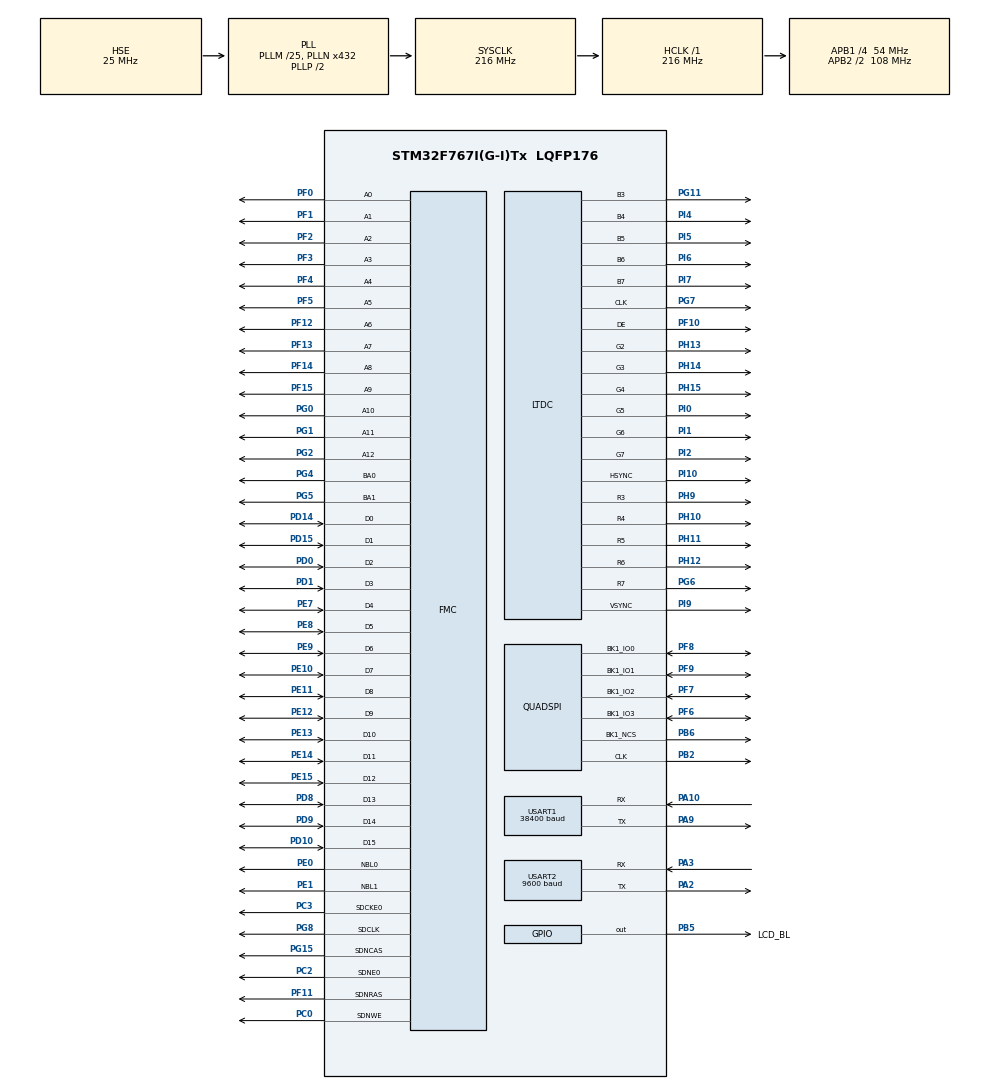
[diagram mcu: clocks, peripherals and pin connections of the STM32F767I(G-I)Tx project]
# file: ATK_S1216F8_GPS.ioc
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CORTEX_M7.AccessPermission_Spec=MPU_REGION_FULL_ACCESS
CORTEX_M7.BaseAddress_Spec=0xC0000000
CORTEX_M7.CPU_DCache=Enabled
CORTEX_M7.CPU_ICache=Enabled
CORTEX_M7.DisableExec_Spec=MPU_INSTRUCTION_ACCESS_ENABLE
CORTEX_M7.Enable_S-Cortex_Memory_Protection_Unit_Region1_Settings_S=__NULL
CORTEX_M7.FlashInterface=TCM_Enabled
CORTEX_M7.IsBufferable_Spec=MPU_ACCESS_BUFFERABLE
CORTEX_M7.IsCacheable_Spec=MPU_ACCESS_CACHEABLE
CORTEX_M7.MPU_Control=MPU_HFNMI_PRIVDEF
CORTEX_M7.Size_Spec=MPU_REGION_SIZE_32MB
CORTEX_M7.SubRegionDisable_Spec=0x0
CORTEX_M7.default_mode_Activation=1
DMA2D.ColorMode=DMA2D_OUTPUT_RGB565
FMC.CASLatency1=FMC_SDRAM_CAS_LATENCY_3
FMC.ColumnBitsNumber1=FMC_SDRAM_COLUMN_BITS_NUM_9
FMC.ExitSelfRefreshDelay1=8
FMC.LoadToActiveDelay1=2
FMC.RCDDelay1=2
FMC.RPDelay1=2
FMC.RPDelay2=2
FMC.ReadBurst1=FMC_SDRAM_RBURST_ENABLE
FMC.ReadBurst2=FMC_SDRAM_RBURST_ENABLE
FMC.ReadPipeDelay1=FMC_SDRAM_RPIPE_DELAY_1
FMC.ReadPipeDelay2=FMC_SDRAM_RPIPE_DELAY_1
FMC.RowCycleDelay1=6
FMC.RowCycleDelay2=6
FMC.SDClockPeriod1=FMC_SDRAM_CLOCK_PERIOD_2
FMC.SDClockPeriod2=FMC_SDRAM_CLOCK_PERIOD_2
FMC.SelfRefreshTime1=6
FMC.WriteRecoveryTime1=4
FREERTOS.Tasks01=TouchGFXTask,0,6144,StartTouchGFXask,Default,NULL,Dynamic,NULL,NULL;Task02,0,1024,StartTask02,Default,NULL,Dynamic,NULL,NULL
FREERTOS.configENABLE_FPU=1
FREERTOS.configTOTAL_HEAP_SIZE=61440
FREERTOS.configUSE_APPLICATION_TASK_TAG=1
FREERTOS.configUSE_NEWLIB_REENTRANT=1
LTDC.ActiveH=LCD_HEIGHT
LTDC.ActiveW=LCD_WIDTH
LTDC.Alpha_L0=0xFF
LTDC.FBStartAdress_L0=LAYER0_ADDR
LTDC.HBP=140
LTDC.HFP=160
LTDC.HSync=20
LTDC.ImageHeight_L0=LCD_HEIGHT
LTDC.ImageWidth_L0=LCD_WIDTH
LTDC.Layers=0
LTDC.PixelFormat_L0=LTDC_PIXEL_FORMAT_RGB565
LTDC.VBP=20
LTDC.VFP=12
LTDC.VSync=3
LTDC.WindowX1_L0=LCD_WIDTH
LTDC.WindowY1_L0=LCD_HEIGHT
Mcu.Family=STM32F7
Mcu.Name=STM32F767I(G-I)Tx
Mcu.Package=LQFP176
Mcu.UserConstants=LAYER0_ADDR,0xC0000000;LCD_HEIGHT,600;LCD_WIDTH,1024
NVIC.DMA2D_IRQn=true\:5\:0\:false\:false\:true\:true\:true\:true\:true
NVIC.FMC_IRQn=true\:5\:0\:false\:false\:true\:true\:true\:true\:true
NVIC.FPU_IRQn=true\:5\:0\:false\:false\:true\:true\:true\:false\:true
NVIC.LTDC_ER_IRQn=true\:5\:0\:false\:false\:true\:true\:true\:true\:true
NVIC.LTDC_IRQn=true\:5\:0\:false\:false\:true\:true\:true\:true\:true
NVIC.PriorityGroup=NVIC_PRIORITYGROUP_4
NVIC.QUADSPI_IRQn=true\:5\:0\:false\:false\:true\:true\:true\:true\:true
NVIC.TIM7_IRQn=true\:0\:0\:true\:false\:true\:false\:false\:true\:true
NVIC.TimeBase=TIM7_IRQn
NVIC.TimeBaseIP=TIM7
NVIC.USART1_IRQn=true\:5\:0\:false\:false\:true\:true\:true\:true\:true
NVIC.USART2_IRQn=true\:5\:0\:false\:false\:true\:true\:true\:true\:true
PA10.Mode=Asynchronous
PA10.Signal=USART1_RX
PA13.Mode=Trace_Asynchronous_SW
PA13.Signal=SYS_JTMS-SWDIO
PA14.Mode=Trace_Asynchronous_SW
PA14.Signal=SYS_JTCK-SWCLK
PA2.Mode=Asynchronous
PA2.Signal=USART2_TX
PA3.Mode=Asynchronous
PA3.Signal=USART2_RX
PA9.Mode=Asynchronous
PA9.Signal=USART1_TX
PB2.Mode=Single Bank 1
PB2.Signal=QUADSPI_CLK
PB3.Mode=Trace_Asynchronous_SW
PB3.Signal=SYS_JTDO-SWO
PB5.GPIO_Label=LCD_BL
PB5.GPIO_PuPd=GPIO_PULLUP
PB5.GPIO_Speed=GPIO_SPEED_FREQ_VERY_HIGH
PB5.PinState=GPIO_PIN_SET
PB5.Signal=GPIO_Output
PB6.Mode=Single Bank 1
PB6.Signal=QUADSPI_BK1_NCS
PC0.Signal=FMC_SDNWE
PC2.Mode=SdramChipSelect1_1
PC2.Signal=FMC_SDNE0
PC3.Mode=SdramChipSelect1_1
PC3.Signal=FMC_SDCKE0
PD0.Signal=FMC_D2_DA2
PD1.Signal=FMC_D3_DA3
PD10.Signal=FMC_D15_DA15
PD14.Signal=FMC_D0_DA0
PD15.Signal=FMC_D1_DA1
PD8.Signal=FMC_D13_DA13
PD9.Signal=FMC_D14_DA14
PE0.Signal=FMC_NBL0
PE1.Signal=FMC_NBL1
PE10.Signal=FMC_D7_DA7
PE11.Signal=FMC_D8_DA8
PE12.Signal=FMC_D9_DA9
PE13.Signal=FMC_D10_DA10
PE14.Signal=FMC_D11_DA11
PE15.Signal=FMC_D12_DA12
PE7.Signal=FMC_D4_DA4
PE8.Signal=FMC_D5_DA5
PE9.Signal=FMC_D6_DA6
PF0.Signal=FMC_A0
PF1.Signal=FMC_A1
PF10.GPIO_Mode=GPIO_MODE_AF_PP
PF10.GPIO_PuPd=GPIO_PULLUP
PF10.GPIO_Speed=GPIO_SPEED_FREQ_VERY_HIGH
PF10.Mode=RGB565
PF10.Signal=LTDC_DE
PF11.Signal=FMC_SDNRAS
PF12.Signal=FMC_A6
PF13.Signal=FMC_A7
PF14.Signal=FMC_A8
PF15.Signal=FMC_A9
PF2.Signal=FMC_A2
PF3.Signal=FMC_A3
PF4.Signal=FMC_A4
PF5.Signal=FMC_A5
PF6.Mode=Single Bank 1
PF6.Signal=QUADSPI_BK1_IO3
PF7.Mode=Single Bank 1
PF7.Signal=QUADSPI_BK1_IO2
PF8.Mode=Single Bank 1
PF8.Signal=QUADSPI_BK1_IO0
PF9.Mode=Single Bank 1
PF9.Signal=QUADSPI_BK1_IO1
PG0.Signal=FMC_A10
PG1.Signal=FMC_A11
PG11.GPIO_Mode=GPIO_MODE_AF_PP
PG11.GPIO_PuPd=GPIO_PULLUP
PG11.GPIO_Speed=GPIO_SPEED_FREQ_VERY_HIGH
PG11.Mode=RGB565
PG11.Signal=LTDC_B3
PG15.Signal=FMC_SDNCAS
PG2.Signal=FMC_A12
PG4.Signal=FMC_A14_BA0
PG5.Signal=FMC_A15_BA1
PG6.GPIO_Mode=GPIO_MODE_AF_PP
PG6.GPIO_PuPd=GPIO_PULLUP
PG6.GPIO_Speed=GPIO_SPEED_FREQ_VERY_HIGH
PG6.Mode=RGB565
PG6.Signal=LTDC_R7
PG7.GPIO_Mode=GPIO_MODE_AF_PP
PG7.GPIO_PuPd=GPIO_PULLUP
PG7.GPIO_Speed=GPIO_SPEED_FREQ_VERY_HIGH
PG7.Mode=RGB565
PG7.Signal=LTDC_CLK
PG8.Signal=FMC_SDCLK
PH0/OSC_IN.Mode=HSE-External-Oscillator
PH0/OSC_IN.Signal=RCC_OSC_IN
PH1/OSC_OUT.Mode=HSE-External-Oscillator
PH1/OSC_OUT.Signal=RCC_OSC_OUT
PH10.GPIO_Mode=GPIO_MODE_AF_PP
PH10.GPIO_PuPd=GPIO_PULLUP
PH10.GPIO_Speed=GPIO_SPEED_FREQ_VERY_HIGH
PH10.Mode=RGB565
PH10.Signal=LTDC_R4
PH11.GPIO_Mode=GPIO_MODE_AF_PP
PH11.GPIO_PuPd=GPIO_PULLUP
PH11.GPIO_Speed=GPIO_SPEED_FREQ_VERY_HIGH
PH11.Mode=RGB565
PH11.Signal=LTDC_R5
PH12.GPIO_Mode=GPIO_MODE_AF_PP
PH12.GPIO_PuPd=GPIO_PULLUP
PH12.GPIO_Speed=GPIO_SPEED_FREQ_VERY_HIGH
PH12.Mode=RGB565
PH12.Signal=LTDC_R6
PH13.GPIO_Mode=GPIO_MODE_AF_PP
PH13.GPIO_PuPd=GPIO_PULLUP
PH13.GPIO_Speed=GPIO_SPEED_FREQ_VERY_HIGH
PH13.Mode=RGB565
PH13.Signal=LTDC_G2
PH14.GPIO_Mode=GPIO_MODE_AF_PP
PH14.GPIO_PuPd=GPIO_PULLUP
PH14.GPIO_Speed=GPIO_SPEED_FREQ_VERY_HIGH
PH14.Mode=RGB565
PH14.Signal=LTDC_G3
PH15.GPIO_Mode=GPIO_MODE_AF_PP
PH15.GPIO_PuPd=GPIO_PULLUP
PH15.GPIO_Speed=GPIO_SPEED_FREQ_VERY_HIGH
PH15.Mode=RGB565
PH15.Signal=LTDC_G4
PH9.GPIO_Mode=GPIO_MODE_AF_PP
PH9.GPIO_PuPd=GPIO_PULLUP
PH9.GPIO_Speed=GPIO_SPEED_FREQ_VERY_HIGH
PH9.Mode=RGB565
PH9.Signal=LTDC_R3
PI0.GPIO_Mode=GPIO_MODE_AF_PP
PI0.GPIO_PuPd=GPIO_PULLUP
PI0.GPIO_Speed=GPIO_SPEED_FREQ_VERY_HIGH
PI0.Mode=RGB565
PI0.Signal=LTDC_G5
PI1.GPIO_Mode=GPIO_MODE_AF_PP
PI1.GPIO_PuPd=GPIO_PULLUP
PI1.GPIO_Speed=GPIO_SPEED_FREQ_VERY_HIGH
PI1.Mode=RGB565
PI1.Signal=LTDC_G6
PI10.GPIO_Mode=GPIO_MODE_AF_PP
PI10.GPIO_PuPd=GPIO_PULLUP
PI10.GPIO_Speed=GPIO_SPEED_FREQ_VERY_HIGH
PI10.Mode=RGB565
PI10.Signal=LTDC_HSYNC
PI2.GPIO_Mode=GPIO_MODE_AF_PP
PI2.GPIO_PuPd=GPIO_PULLUP
PI2.GPIO_Speed=GPIO_SPEED_FREQ_VERY_HIGH
PI2.Mode=RGB565
PI2.Signal=LTDC_G7
PI4.GPIO_Mode=GPIO_MODE_AF_PP
PI4.GPIO_PuPd=GPIO_PULLUP
PI4.GPIO_Speed=GPIO_SPEED_FREQ_VERY_HIGH
PI4.Mode=RGB565
PI4.Signal=LTDC_B4
PI5.GPIO_Mode=GPIO_MODE_AF_PP
PI5.GPIO_PuPd=GPIO_PULLUP
PI5.GPIO_Speed=GPIO_SPEED_FREQ_VERY_HIGH
PI5.Mode=RGB565
PI5.Signal=LTDC_B5
PI6.GPIO_Mode=GPIO_MODE_AF_PP
PI6.GPIO_PuPd=GPIO_PULLUP
PI6.GPIO_Speed=GPIO_SPEED_FREQ_VERY_HIGH
PI6.Mode=RGB565
PI6.Signal=LTDC_B6
PI7.GPIO_Mode=GPIO_MODE_AF_PP
PI7.GPIO_PuPd=GPIO_PULLUP
PI7.GPIO_Speed=GPIO_SPEED_FREQ_VERY_HIGH
PI7.Mode=RGB565
PI7.Signal=LTDC_B7
PI9.GPIO_Mode=GPIO_MODE_AF_PP
PI9.GPIO_PuPd=GPIO_PULLUP
PI9.GPIO_Speed=GPIO_SPEED_FREQ_VERY_HIGH
PI9.Mode=RGB565
PI9.Signal=LTDC_VSYNC
ProjectManager.HeapSize=0x200
ProjectManager.StackSize=0x400
ProjectManager.TargetToolchain=STM32CubeIDE
QUADSPI.ChipSelectHighTime=QSPI_CS_HIGH_TIME_4_CYCLE
QUADSPI.ClockMode=QSPI_CLOCK_MODE_3
QUADSPI.ClockPrescaler=2
QUADSPI.FifoThreshold=4
QUADSPI.SampleShifting=QSPI_SAMPLE_SHIFTING_HALFCYCLE
RCC.AHBFreq_Value=216000000
RCC.APB1CLKDivider=RCC_HCLK_DIV4
RCC.APB1Freq_Value=54000000
RCC.APB1TimFreq_Value=108000000
RCC.APB2CLKDivider=RCC_HCLK_DIV2
RCC.APB2Freq_Value=108000000
RCC.APB2TimFreq_Value=216000000
RCC.CortexFreq_Value=216000000
RCC.HCLKFreq_Value=216000000
RCC.HSE_VALUE=25000000
RCC.HSI_VALUE=16000000
RCC.LSE_VALUE=32768
RCC.PLLM=25
RCC.PLLN=432
RCC.PLLSAIN=408
RCC.PLLSAIR=4
RCC.PLLSourceVirtual=RCC_PLLSOURCE_HSE
RCC.SYSCLKFreq_VALUE=216000000
RCC.SYSCLKSource=RCC_SYSCLKSOURCE_PLLCLK
RCC.USBFreq_Value=216000000
RCC.VCOOutputFreq_Value=432000000
SH.FMC_A0.0=FMC_A0,13b-sda1
SH.FMC_A1.0=FMC_A1,13b-sda1
SH.FMC_A10.0=FMC_A10,13b-sda1
SH.FMC_A11.0=FMC_A11,13b-sda1
SH.FMC_A12.0=FMC_A12,13b-sda1
SH.FMC_A14_BA0.0=FMC_BA0,FourSdramBanks1
SH.FMC_A15_BA1.0=FMC_BA1,FourSdramBanks1
SH.FMC_A2.0=FMC_A2,13b-sda1
SH.FMC_A3.0=FMC_A3,13b-sda1
SH.FMC_A4.0=FMC_A4,13b-sda1
SH.FMC_A5.0=FMC_A5,13b-sda1
SH.FMC_A6.0=FMC_A6,13b-sda1
SH.FMC_A7.0=FMC_A7,13b-sda1
SH.FMC_A8.0=FMC_A8,13b-sda1
SH.FMC_A9.0=FMC_A9,13b-sda1
SH.FMC_D0_DA0.0=FMC_D0,sd-16b-d1
SH.FMC_D10_DA10.0=FMC_D10,sd-16b-d1
SH.FMC_D11_DA11.0=FMC_D11,sd-16b-d1
SH.FMC_D12_DA12.0=FMC_D12,sd-16b-d1
SH.FMC_D13_DA13.0=FMC_D13,sd-16b-d1
SH.FMC_D14_DA14.0=FMC_D14,sd-16b-d1
SH.FMC_D15_DA15.0=FMC_D15,sd-16b-d1
SH.FMC_D1_DA1.0=FMC_D1,sd-16b-d1
SH.FMC_D2_DA2.0=FMC_D2,sd-16b-d1
SH.FMC_D3_DA3.0=FMC_D3,sd-16b-d1
SH.FMC_D4_DA4.0=FMC_D4,sd-16b-d1
SH.FMC_D5_DA5.0=FMC_D5,sd-16b-d1
SH.FMC_D6_DA6.0=FMC_D6,sd-16b-d1
SH.FMC_D7_DA7.0=FMC_D7,sd-16b-d1
SH.FMC_D8_DA8.0=FMC_D8,sd-16b-d1
SH.FMC_D9_DA9.0=FMC_D9,sd-16b-d1
SH.FMC_NBL0.0=FMC_NBL0,Sd2ByteEnable1
SH.FMC_NBL1.0=FMC_NBL1,Sd2ByteEnable1
SH.FMC_SDCLK.0=FMC_SDCLK,13b-sda1
SH.FMC_SDNCAS.0=FMC_SDNCAS,13b-sda1
SH.FMC_SDNRAS.0=FMC_SDNRAS,13b-sda1
SH.FMC_SDNWE.0=FMC_SDNWE,13b-sda1
STMicroelectronics.X-CUBE-TOUCHGFX.4.18.1.ApplicationCcGraphicsJjApplication=TouchGFXOoGenerator
STMicroelectronics.X-CUBE-TOUCHGFX.4.18.1.tgfx_address1=0xC0000000
STMicroelectronics.X-CUBE-TOUCHGFX.4.18.1.tgfx_address2=0xC012C000
STMicroelectronics.X-CUBE-TOUCHGFX.4.18.1.tgfx_buffering_strategy=Double
STMicroelectronics.X-CUBE-TOUCHGFX.4.18.1.tgfx_display_interface=disp_ltdc
STMicroelectronics.X-CUBE-TOUCHGFX.4.18.1.tgfx_hardware_accelerator=dma_2d
STMicroelectronics.X-CUBE-TOUCHGFX.4.18.1.tgfx_location=By Address
STMicroelectronics.X-CUBE-TOUCHGFX.4.18.1.tgfx_vsync=vsync_ltdc
STMicroelectronics.X-CUBE-TOUCHGFX.4.18.1_IsPackSelfContextualization=true
USART1.BaudRate=38400
USART1.VirtualMode-Asynchronous=VM_ASYNC
USART2.BaudRate=9600
USART2.VirtualMode-Asynchronous=VM_ASYNC
VP_CRC_VS_CRC.Mode=CRC_Activate
VP_DMA2D_VS_DMA2D.Mode=DMA2D_Activate
VP_FREERTOS_VS_CMSIS_V1.Mode=CMSIS_V1
VP_STMicroelectronics.X-CUBE-TOUCHGFX_VS_GraphicsJjApplication_4.18.1.Mode=GraphicsJjApplication
VP_SYS_VS_tim7.Mode=TIM7
board=custom

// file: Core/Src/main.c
/* USER CODE BEGIN Header */
/**
 ******************************************************************************
 * @file           : main.c
 * @brief          : Main program body
 ******************************************************************************
 * @attention
 *
 * Copyright (c) 2022 STMicroelectronics.
 * All rights reserved.
 *
 * This software is licensed under terms that can be found in the LICENSE file
 * in the root directory of this software component.
 * If no LICENSE file comes with this software, it is provided AS-IS.
 *
 ******************************************************************************
 */
/* USER CODE END Header */
#include "main.h"
#include "cmsis_os.h"
#include "crc.h"
#include "dma2d.h"
#include "ltdc.h"
#include "quadspi.h"
#include "usart.h"
#include "gpio.h"
#include "fmc.h"
#include "app_touchgfx.h"

/* USER CODE BEGIN Includes */
#include "sensors.h"
#include <stdio.h>
/* USER CODE END Includes */

/* USER CODE BEGIN PD */
#define REFRESH_COUNT 1755

#define SDRAM_TIMEOUT ((uint32_t)0xFFFF)
#define SDRAM_MODEREG_BURST_LENGTH_1 ((uint16_t)0x0000)
#define SDRAM_MODEREG_BURST_LENGTH_2 ((uint16_t)0x0001)
#define SDRAM_MODEREG_BURST_LENGTH_4 ((uint16_t)0x0002)
#define SDRAM_MODEREG_BURST_LENGTH_8 ((uint16_t)0x0004)
#define SDRAM_MODEREG_BURST_TYPE_SEQUENTIAL ((uint16_t)0x0000)
#define SDRAM_MODEREG_BURST_TYPE_INTERLEAVED ((uint16_t)0x0008)
#define SDRAM_MODEREG_CAS_LATENCY_2 ((uint16_t)0x0020)
#define SDRAM_MODEREG_CAS_LATENCY_3 ((uint16_t)0x0030)
#define SDRAM_MODEREG_OPERATING_MODE_STANDARD ((uint16_t)0x0000)
#define SDRAM_MODEREG_WRITEBURST_MODE_PROGRAMMED ((uint16_t)0x0000)
#define SDRAM_MODEREG_WRITEBURST_MODE_SINGLE ((uint16_t)0x0200)
/* USER CODE END PD */

/* USER CODE BEGIN PV */
static FMC_SDRAM_CommandTypeDef Command;
/* USER CODE END PV */

void SystemClock_Config(void);
static void MPU_Config(void);
void MX_FREERTOS_Init(void);

int main(void)
{

  /* MPU Configuration--------------------------------------------------------*/
  MPU_Config();

  /* Enable I-Cache---------------------------------------------------------*/
  SCB_EnableICache();

  /* Enable D-Cache---------------------------------------------------------*/
  SCB_EnableDCache();

  /* MCU Configuration--------------------------------------------------------*/

  /* Reset of all peripherals, Initializes the Flash interface and the Systick. */
  HAL_Init();

  /* Configure the system clock */
  SystemClock_Config();

  /* Initialize all configured peripherals */
  MX_GPIO_Init();
  MX_USART1_UART_Init();
  MX_USART2_UART_Init();
  MX_DMA2D_Init();
  MX_FMC_Init();
  MX_QUADSPI_Init();
  MX_CRC_Init();
  MX_LTDC_Init();
  MX_TouchGFX_Init();
  /* USER CODE BEGIN 2 */
  MX_SDRAM_InitEx();
  HAL_UART_Receive_IT(&huart1, (uint8_t *)UART1_temp, REC_LENGTH);
  printf("USART2 IS OK!!!\r\n");
  /* USER CODE END 2 */

  /* Call init function for freertos objects (in freertos.c) */
  MX_FREERTOS_Init();

  /* Start scheduler */
  osKernelStart();

  /* We should never get here as control is now taken by the scheduler */
  /* Infinite loop */
  while (1) {

  }
}

void SystemClock_Config(void)
{
  RCC_OscInitTypeDef RCC_OscInitStruct = {0};
  RCC_ClkInitTypeDef RCC_ClkInitStruct = {0};

  /** Configure the main internal regulator output voltage
  */
  __HAL_RCC_PWR_CLK_ENABLE();
  __HAL_PWR_VOLTAGESCALING_CONFIG(PWR_REGULATOR_VOLTAGE_SCALE1);

  /** Initializes the RCC Oscillators according to the specified parameters
  * in the RCC_OscInitTypeDef structure.
  */
  RCC_OscInitStruct.OscillatorType = RCC_OSCILLATORTYPE_HSE;
  RCC_OscInitStruct.HSEState = RCC_HSE_ON;
  RCC_OscInitStruct.PLL.PLLState = RCC_PLL_ON;
  RCC_OscInitStruct.PLL.PLLSource = RCC_PLLSOURCE_HSE;
  RCC_OscInitStruct.PLL.PLLM = 25;
  RCC_OscInitStruct.PLL.PLLN = 432;
  RCC_OscInitStruct.PLL.PLLP = RCC_PLLP_DIV2;
  RCC_OscInitStruct.PLL.PLLQ = 2;
  RCC_OscInitStruct.PLL.PLLR = 2;
  if (HAL_RCC_OscConfig(&RCC_OscInitStruct) != HAL_OK)
  {
    Error_Handler();
  }

  /** Activate the Over-Drive mode
  */
  if (HAL_PWREx_EnableOverDrive() != HAL_OK)
  {
    Error_Handler();
  }

  /** Initializes the CPU, AHB and APB buses clocks
  */
  RCC_ClkInitStruct.ClockType = RCC_CLOCKTYPE_HCLK|RCC_CLOCKTYPE_SYSCLK
                              |RCC_CLOCKTYPE_PCLK1|RCC_CLOCKTYPE_PCLK2;
  RCC_ClkInitStruct.SYSCLKSource = RCC_SYSCLKSOURCE_PLLCLK;
  RCC_ClkInitStruct.AHBCLKDivider = RCC_SYSCLK_DIV1;
  RCC_ClkInitStruct.APB1CLKDivider = RCC_HCLK_DIV4;
  RCC_ClkInitStruct.APB2CLKDivider = RCC_HCLK_DIV2;

  if (HAL_RCC_ClockConfig(&RCC_ClkInitStruct, FLASH_LATENCY_7) != HAL_OK)
  {
    Error_Handler();
  }
}

/* USER CODE BEGIN 4 */
/**
 * @brief  Programs the SDRAM device.
 * @retval None
 */
void MX_SDRAM_InitEx(void) {
  __IO uint32_t tmpmrd = 0;

  /* Step 1: Configure a clock configuration enable command */
  Command.CommandMode = FMC_SDRAM_CMD_CLK_ENABLE;
  Command.CommandTarget = FMC_SDRAM_CMD_TARGET_BANK1;
  Command.AutoRefreshNumber = 1;
  Command.ModeRegisterDefinition = 0;

  /* Send the command */
  HAL_SDRAM_SendCommand(&hsdram1, &Command, SDRAM_TIMEOUT);

  /* Step 2: Insert 100 us minimum delay */
  /* Inserted delay is equal to 1 ms due to systick time base unit (ms) */
  HAL_Delay(1);

  /* Step 3: Configure a PALL (precharge all) command */
  Command.CommandMode = FMC_SDRAM_CMD_PALL;
  Command.CommandTarget = FMC_SDRAM_CMD_TARGET_BANK1;
  Command.AutoRefreshNumber = 1;
  Command.ModeRegisterDefinition = 0;

  /* Send the command */
  HAL_SDRAM_SendCommand(&hsdram1, &Command, SDRAM_TIMEOUT);

  /* Step 4: Configure an Auto Refresh command */
  Command.CommandMode = FMC_SDRAM_CMD_AUTOREFRESH_MODE;
  Command.CommandTarget = FMC_SDRAM_CMD_TARGET_BANK1;
  Command.AutoRefreshNumber = 8;
  Command.ModeRegisterDefinition = 0;

  /* Send the command */
  HAL_SDRAM_SendCommand(&hsdram1, &Command, SDRAM_TIMEOUT);

  /* Step 5: Program the external memory mode register */
  tmpmrd = (uint32_t)SDRAM_MODEREG_BURST_LENGTH_1 |
           SDRAM_MODEREG_BURST_TYPE_SEQUENTIAL | SDRAM_MODEREG_CAS_LATENCY_3 |
           SDRAM_MODEREG_OPERATING_MODE_STANDARD |
           SDRAM_MODEREG_WRITEBURST_MODE_SINGLE;

  Command.CommandMode = FMC_SDRAM_CMD_LOAD_MODE;
  Command.CommandTarget = FMC_SDRAM_CMD_TARGET_BANK1;
  Command.AutoRefreshNumber = 1;
  Command.ModeRegisterDefinition = tmpmrd;

  /* Send the command */
  HAL_SDRAM_SendCommand(&hsdram1, &Command, SDRAM_TIMEOUT);

  /* Step 6: Set the refresh rate counter */
  /* Set the device refresh rate */
  HAL_SDRAM_ProgramRefreshRate(&hsdram1, REFRESH_COUNT);
}
/* USER CODE END 4 */

/* MPU Configuration */

void MPU_Config(void)
{
  MPU_Region_InitTypeDef MPU_InitStruct = {0};

  /* Disables the MPU */
  HAL_MPU_Disable();

  /** Initializes and configures the Region and the memory to be protected
  */
  MPU_InitStruct.Enable = MPU_REGION_ENABLE;
  MPU_InitStruct.Number = MPU_REGION_NUMBER0;
  MPU_InitStruct.BaseAddress = 0xC0000000;
  MPU_InitStruct.Size = MPU_REGION_SIZE_32MB;
  MPU_InitStruct.SubRegionDisable = 0x0;
  MPU_InitStruct.TypeExtField = MPU_TEX_LEVEL0;
  MPU_InitStruct.AccessPermission = MPU_REGION_FULL_ACCESS;
  MPU_InitStruct.DisableExec = MPU_INSTRUCTION_ACCESS_ENABLE;
  MPU_InitStruct.IsShareable = MPU_ACCESS_SHAREABLE;
  MPU_InitStruct.IsCacheable = MPU_ACCESS_CACHEABLE;
  MPU_InitStruct.IsBufferable = MPU_ACCESS_BUFFERABLE;

  HAL_MPU_ConfigRegion(&MPU_InitStruct);
  /* Enables the MPU */
  HAL_MPU_Enable(MPU_HFNMI_PRIVDEF);

}

void HAL_TIM_PeriodElapsedCallback(TIM_HandleTypeDef *htim)
{
  if (htim->Instance == TIM7) {
    HAL_IncTick();
  }
}

void Error_Handler(void)
{
  __disable_irq();
  while (1) {
  }
}

#ifdef  USE_FULL_ASSERT
/**
  * @brief  Reports the name of the source file and the source line number
  *         where the assert_param error has occurred.
  * @param  file: pointer to the source file name
  * @param  line: assert_param error line source number
  * @retval None
  */
void assert_failed(uint8_t *file, uint32_t line)
{
  /* USER CODE BEGIN 6 */
  /* User can add his own implementation to report the file name and line
     number,
     ex: printf("Wrong parameters value: file %s on line %d\r\n", file, line) */
  /* USER CODE END 6 */
}
#endif /* USE_FULL_ASSERT */

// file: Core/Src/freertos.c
/* USER CODE BEGIN Header */
/**
 ******************************************************************************
 * File Name          : freertos.c
 * Description        : Code for freertos applications
 ******************************************************************************
 * @attention
 *
 * Copyright (c) 2022 STMicroelectronics.
 * All rights reserved.
 *
 * This software is licensed under terms that can be found in the LICENSE file
 * in the root directory of this software component.
 * If no LICENSE file comes with this software, it is provided AS-IS.
 *
 ******************************************************************************
 */
/* USER CODE END Header */

#include "FreeRTOS.h"
#include "cmsis_os.h"
#include "main.h"
#include "task.h"

/* USER CODE BEGIN Includes */
#include "app_touchgfx.h"
#include "cgi210.h"
/* USER CODE END Includes */

osThreadId TouchGFXTaskHandle;
osThreadId Task02Handle;

void StartTouchGFXask(void const *argument);
void StartTask02(void const *argument);

void MX_FREERTOS_Init(void); /* (MISRA C 2004 rule 8.1) */

/* GetIdleTaskMemory prototype (linked to static allocation support) */
void vApplicationGetIdleTaskMemory(StaticTask_t **ppxIdleTaskTCBBuffer,
                                   StackType_t **ppxIdleTaskStackBuffer,
                                   uint32_t *pulIdleTaskStackSize);

/* USER CODE BEGIN GET_IDLE_TASK_MEMORY */
static StaticTask_t xIdleTaskTCBBuffer;
static StackType_t xIdleStack[configMINIMAL_STACK_SIZE];

void vApplicationGetIdleTaskMemory(StaticTask_t **ppxIdleTaskTCBBuffer,
                                   StackType_t **ppxIdleTaskStackBuffer,
                                   uint32_t *pulIdleTaskStackSize) {
  *ppxIdleTaskTCBBuffer = &xIdleTaskTCBBuffer;
  *ppxIdleTaskStackBuffer = &xIdleStack[0];
  *pulIdleTaskStackSize = configMINIMAL_STACK_SIZE;
  /* place for user code */
}
/* USER CODE END GET_IDLE_TASK_MEMORY */

void MX_FREERTOS_Init(void) {

  /* Create the thread(s) */
  /* definition and creation of TouchGFXTask */
  osThreadDef(TouchGFXTask, StartTouchGFXask, osPriorityNormal, 0, 6144);
  TouchGFXTaskHandle = osThreadCreate(osThread(TouchGFXTask), NULL);

  /* definition and creation of Task02 */
  osThreadDef(Task02, StartTask02, osPriorityNormal, 0, 1024);
  Task02Handle = osThreadCreate(osThread(Task02), NULL);

}

void StartTouchGFXask(void const *argument) {
  /* USER CODE BEGIN StartTouchGFXask */
  MX_TouchGFX_Process();
  /* Infinite loop */
  for (;;) {
    osDelay(1);
  }
  /* USER CODE END StartTouchGFXask */
}

void StartTask02(void const *argument) {
  /* USER CODE BEGIN StartTask02 */
  /* Infinite loop */
  for (;;) {
    Data_Record_Add_New_Frame();
    osDelay(10);
  }
  /* USER CODE END StartTask02 */
}
